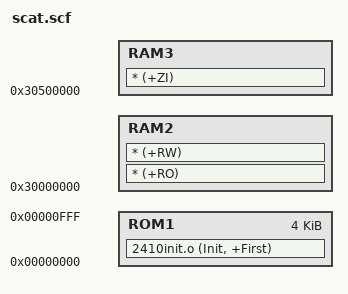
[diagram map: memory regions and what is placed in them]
LDR1 0x00000000 
{
    ROM1 0x00000000  0x1000
    {
        2410init.o (Init, +First)
    }
}
LDR2 0x30000000
{
    RAM2 0x30000000  
    {
	* (+RO)  
	* (+RW)
    }
    RAM3 0x30500000
    {
    	* (+ZI)
    }
}

